# CY8C4248AZI_L485 register map
File version: 0.1
Registers are 32-bit, read-write, no defined reset value unless marked. A register's access mark holds for its fields unless they carry their own. Offsets are from the block's base; [hi:lo] are bit positions; {n}, {i} and the like mark numbered series; 'fields as' and 'values as' point back to an identical list.

## CAN
Base 0x00000000
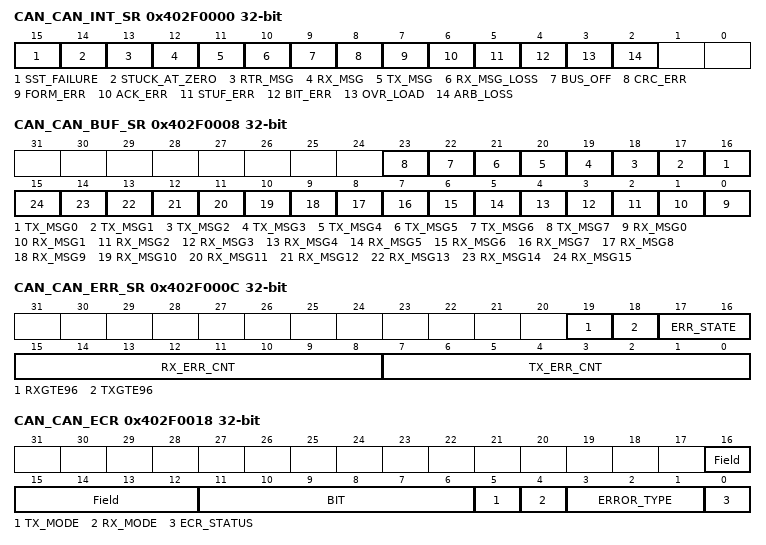
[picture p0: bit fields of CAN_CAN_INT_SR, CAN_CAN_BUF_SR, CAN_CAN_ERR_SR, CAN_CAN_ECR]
0x402F0000 CAN_CAN_INT_SR — The interrupt status register stores internal interrupt events. ? Once a bit is set it remains set until it is cleared by writing a '1' to it. ? The interrupt enable register has no effect on the interrupt status register. ? A pending interrupt occurs when the flag is set to '1'. To acknowledge an interrupt, set the flag to '1'
  [15] SST_FAILURE — Single shot transmission failure
  [14] STUCK_AT_ZERO — Stuck at dominant error
  [13] RTR_MSG — RTR auto-reply message sent
  [12] RX_MSG — Msg Recieved
  [11] TX_MSG — Tx msg Sent
  [10] RX_MSG_LOSS — Rx msg loss Interrupt
  [9] BUS_OFF — Bus Off State
  [8] CRC_ERR — CRC Error Interrupt
  [7] FORM_ERR — Form Error Interrupt
  [6] ACK_ERR — Ack Error Interrupt
  [5] STUF_ERR — Stuff Error Interrupt
  [4] BIT_ERR — Bit Error Interrupt
  [3] OVR_LOAD — Overload Interrupt
  [2] ARB_LOSS — Arbitration Loss
0x402F0008 CAN_CAN_BUF_SR — These status indicators bundle the respective flags from all RxMessage and TxMessage buffers. ? Note All flags are read only. To acknowledge a MsgAv flag, the CPU must write to the respective RxMessage buffer
  [n+16] TX_MSG{n} (n=0..7) — Tx req Pending for Tx Msg{n}
  [n] RX_MSG{n} (n=0..15) — Rx Msg{n} Available
0x402F000C CAN_CAN_ERR_SR — Status indicators are provided to report the CAN controller error state, receive error count, and transmit error count. ? Special flags report error counter values equal to or in excess of 96 errors are available to indicate heavily disturbed bus situations. ? The transmitter error counter according to the CAN standard. When it is greater than 255 Decimal, it is fixed at 255 Decimal.
  [19] RXGTE96 — Rx Error Count is greater or equal to 96 Decimal
  [18] TXGTE96 — Tx Error Count is greater or equal to 96 Decimal
  [17:16] ERR_STATE — Error State of CAN node, 00 error active, 01 error passive, 1x bus off
  [15:8] RX_ERR_CNT — Rx error Count. When in bus-off state,this counter is used to count 128 groups of 11 recessive bits
  [7:0] TX_ERR_CNT — Tx error Count
0x402F0018 CAN_CAN_ECR — The Error Capture register operates in two different modes: ? Free running mode - ECR displays the fiels and bit positions within the current CAN frame ? Error Capture mode - ECR samples the field and bit position when a CAN error is detected ? In order to sample such an event, the ECR needs to be armed by performing a write access to it. ? When armed, the ECR only captures one error event. ? For successive error captures, the ECR needs to be armed again.
  [16:12] Field ro — Field: ? 0x00 : Stopped ? 0x01 : Synchronize ? 0x05 : Interframe ? 0x06 : Bus Idle ? 0x07 : Start of Frame ? 0x08 : Arbitration ? 0x09 : Control ? 0x0A : Data ? 0x0B : CRC ? 0x0C : ACK ? 0x0D : End of frame ? 0x10 : Error flag ? 0x11 : Error echo ? 0x12 : Error delimiter ? 0x18 : Overload flag ? 0x19 : Overload echo ? 0x1A : Overload delimiter ? Others : N/A
  [11:6] BIT ro — Bit number inside of Field
  [5] TX_MODE ro — TX Mode: ? 0: No status ? 1: CAN Controller is transmitter
  [4] RX_MODE ro — RX Mode: ? 0: No status ? 1: CAN Controller is receiver
  [3:1] ERROR_TYPE ro — Error type: ? 000 : Arbitration loss ? 001 : Bit Error ? 010 : Bit Stuffing Error ? 011 : Acknowledge Error ? 100 : Form Error ? 101 : CRC Error ? Others : N/A
  [0] ECR_STATUS — ECR STATUS: ? 0: ECR register captured an error, or it is in free running mode ? 1: ECR register is armed
{0x402F0024+0x10*i} CAN_CAN_TX{i}_ID (i=0..7) — CAN Tx Msg Identifier
  [31:3] ID — Tx Msg Indentifier
{0x402F0028+0x10*i} CAN_CAN_TX{i}_DH (i=0..7) — CAN Tx Msg Upper Data Bytes
  [31:0] DATA_HIGH — Upper Data Bytes
{0x402F002C+0x10*i} CAN_CAN_TX{i}_DL (i=0..7) — CAN Tx Msg Lower Data Bytes
  [31:0] DATA_LOW — Lower Data Bytes
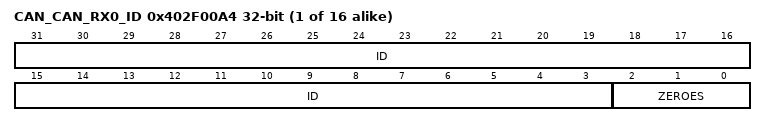
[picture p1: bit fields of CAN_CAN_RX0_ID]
{0x402F00A4+0x20*i} CAN_CAN_RX{i}_ID (i=0..15) — The register contains Rx Msg Identifier
  [31:3] ID — Rx Msg Indentifier
  [2:0] ZEROES — zeros
{0x402F00A8+0x20*i} CAN_CAN_RX{i}_DH (i=0..15) — The register contains the Rx Msg Upper Data Bytes
  [31:0] DATA_HIGH — Upper Data Bytes
{0x402F00AC+0x20*i} CAN_CAN_RX{i}_DL (i=0..15) — The register contains the Rx Msg Lover Data Bytes
  [31:0] DATA_LOW — Lower Data Bytes

## QuadDec
Base 0x00000000
0x400F0000 QuadDec_Cnt16_COUNTER 16-bit — Counter value
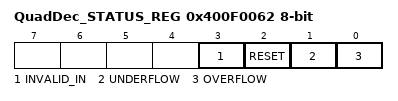
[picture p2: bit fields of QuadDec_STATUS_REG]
0x400F0062 QuadDec_STATUS_REG 8-bit — Quadrature Decoder Status Register
  [3] INVALID_IN ro — Invalid state transition on the A and B inputs
  [2] RESET ro — Counter Reset due index
  [1] UNDERFLOW ro — Counter underflow
  [0] OVERFLOW ro — Counter overflow

## QuadDec_Cnt16
Base 0x00000000; alternate view of QuadDec
0x400F0000 QuadDec_Cnt16_COUNTER 16-bit — UDB.A0 - Current Counter Value
0x400F0020 QuadDec_Cnt16_PERIOD 16-bit — UDB.D0 - Assigned Period
0x400F0030 QuadDec_Cnt16_COMPARE 16-bit — UDB.D1 - Assigned Compare Value
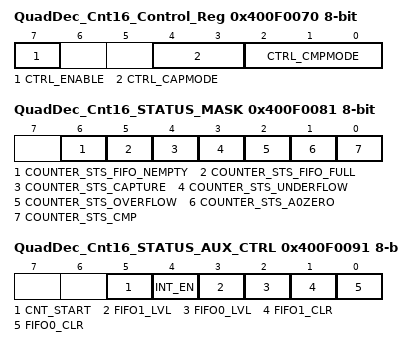
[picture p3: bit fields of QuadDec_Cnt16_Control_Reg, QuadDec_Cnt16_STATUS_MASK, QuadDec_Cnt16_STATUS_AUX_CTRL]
0x400F0070 QuadDec_Cnt16_Control_Reg 8-bit — UDB Control Register - Assigned Control Register Value
  [7] CTRL_ENABLE — Enable Counter
  [4:3] CTRL_CAPMODE — Capture mode
  [2:0] CTRL_CMPMODE — Compare mode
0x400F0081 QuadDec_Cnt16_STATUS_MASK 8-bit — UDB Status bits Interrupt Mask Enable Register
  [6] COUNTER_STS_FIFO_NEMPTY — FIFO Not Empty Status
  [5] COUNTER_STS_FIFO_FULL — FIFO Full Status
  [4] COUNTER_STS_CAPTURE — Capture Status
  [3] COUNTER_STS_UNDERFLOW — Underflow status
  [2] COUNTER_STS_OVERFLOW — Overflow status
  [1] COUNTER_STS_A0ZERO — A0 Zero ouput status
  [0] COUNTER_STS_CMP — Compare output status
0x400F0091 QuadDec_Cnt16_STATUS_AUX_CTRL 8-bit — UDB Auxilliary Control Register
  [5] CNT_START — FIFO0 clear
    0=E_CNT_START0 (Disable counter); 1=E_CNT_START1 (Enable counter)
  [4] INT_EN
    0=E_INT_EN0 (Interrupt disabled); 1=E_INT_EN1 (Interrupt enabled)
  [3] FIFO1_LVL — FIFO level
    0=E_FIFO_LVL_0 (FIFO LVL: input mode: FIFO not full; output mode: FIFO not empty); 1=E_FIFO_LVL_1 (FIFO LVL: input mode: FIFO at least 1/2 empty; output mode: FIFO at least 1/2 full)
  [2] FIFO0_LVL — FIFO level
    values as FIFO1_LVL
  [1] FIFO1_CLR — FIFO1 clear
    0=E_FIFO_CLR_0 (Normal FIFO operation); 1=E_FIFO_CLR_1 (Clear FIFO state)
  [0] FIFO0_CLR — FIFO0 clear
    values as FIFO1_CLR

## PWM_Motor
Base 0x00000000
0x40200108 COUNTER — Current counter value
0x4020010C CC — Compare / capture value
0x40200110 CC_BUF — Compare / capture buffer value
0x40200114 PERIOD — Period value
0x40200118 PERIOD_BUF — Period buffer value

## StripLights_StringSel
Base 0x00000000
0x400F0075 StripLights_StringSel_CONTROL_REG 8-bit

## Status_Reg_Switches
Base 0x00000000
0x400F0064 Status_Reg_Switches_STATUS_REG 8-bit
0x400F0084 Status_Reg_Switches_MASK_REG 8-bit
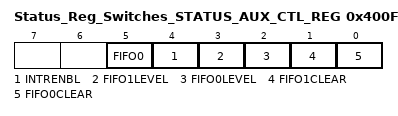
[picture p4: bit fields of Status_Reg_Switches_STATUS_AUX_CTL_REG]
0x400F0094 Status_Reg_Switches_STATUS_AUX_CTL_REG 8-bit
  [5] FIFO0 — FIFO0 clear
    1=ENABLED (Enable counter); 0=DISABLED (Disable counter)
  [4] INTRENBL — Enables or disables the Interrupt
    1=ENABLED (Interrupt enabled); 0=DISABLED (Interrupt disabled)
  [3] FIFO1LEVEL — FIFO level
    1=ENABLED (FIFO LVL: input mode: FIFO at least 1/2 empty; output mode: FIFO at least 1/2 full); 0=DISABLED (FIFO LVL: input mode: FIFO not full; output mode: FIFO not empty)
  [2] FIFO0LEVEL — FIFO level
    values as FIFO1LEVEL
  [1] FIFO1CLEAR — FIFO clear
    1=ENABLED (Clear FIFO state); 0=DISABLED (Normal FIFO operation)
  [0] FIFO0CLEAR — FIFO clear
    values as FIFO1CLEAR
